# TREMO register map
File version: 1.6.2
CPU: CM4 r0p1, little endian, MPU, FPU, 3 interrupt priority bits
Registers are 32-bit, read-write, reset 0x0 unless marked. A register's access mark holds for its fields unless they carry their own. Offsets are from the block's base; [hi:lo] are bit positions; {n}, {i} and the like mark numbered series.

## SSP0
Base 0x40006000
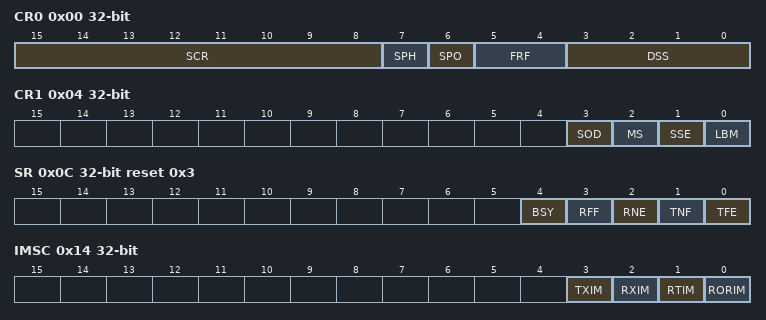
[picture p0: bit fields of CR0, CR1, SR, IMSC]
0x00 CR0 — control register 0
  [15:8] SCR — Serial clock rate
  [7] SPH — SSP phase setting
  [6] SPO — SSP polarity setting
  [5:4] FRF — SSP frame formats setting
  [3:0] DSS — Data width setting
0x04 CR1 — control register 1
  [3] SOD — SSP output disable in slave mode
  [2] MS — Master/slave mode selection
  [1] SSE — SSP enable
  [0] LBM — loopback mode
0x08 DR — data register
  [15:0] DATA
0x0C SR ro reset 0x3 — status register
  [4] BSY — SSP busy flag
  [3] RFF — RX FIFO full flag
  [2] RNE — RX FIFO not empty flag
  [1] TNF — TX FIFO not full flag
  [0] TFE — TX FIFO empty flag
0x10 CPSR — clock prescale register
  [7:0] CPSDVSR — Clock prescaler divider, must be an even number between 2~254
0x14 IMSC — interrupt mask set or clear register
  [3] TXIM — TX interrupt mask bit
  [2] RXIM — RX interrupt mask bit
  [1] RTIM — RX timeout interrupt mask bit
  [0] RORIM — RX overrun interrupt mask bit
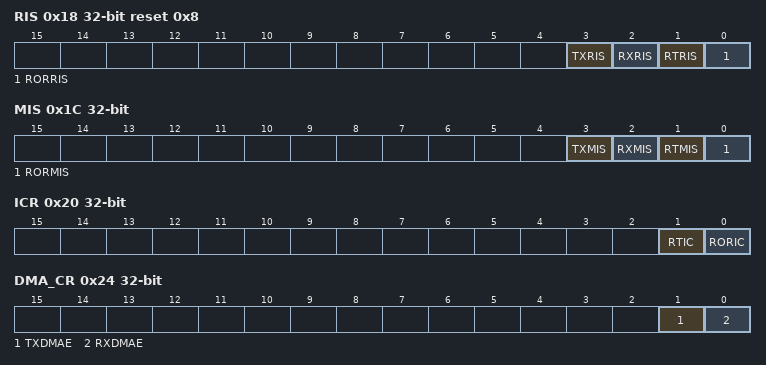
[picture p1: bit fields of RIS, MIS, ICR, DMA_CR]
0x18 RIS ro reset 0x8 — raw interrupt status register
  [3] TXRIS — TX raw interrupt status
  [2] RXRIS — RX raw interrupt status
  [1] RTRIS — RX timeout raw interrupt status
  [0] RORRIS — RX overrun raw interrupt status
0x1C MIS ro — masked interrupt status register
  [3] TXMIS — TX masked interrupt status
  [2] RXMIS — RX masked interrupt status
  [1] RTMIS — RX timeout masked interrupt status
  [0] RORMIS — RX overrun masked interrupt status
0x20 ICR wo — interrupt clear register
  [1] RTIC — RX timeout interrupt clear
  [0] RORIC — RX overrun interrupt clear
0x24 DMA_CR — DMA control register
  [1] TXDMAE — DMA TX enable
  [0] RXDMAE — DMA RX enable
{0xFE0+4i} PERIPH_ID{i} ro (i=0..3) — peripheral identification register {i}
{0xFF0+4i} PCELL_ID{i} ro (i=0..3) — prime cell identification register {i}

## SSP1
Base 0x40012000
Same registers: SSP2 0x40013000
Registers as SSP0; these are added or differ:
0x08 DR — data register
  [15:0] DATA — SSP TX/RX data

## LPUART — Low power UART
Base 0x40005000
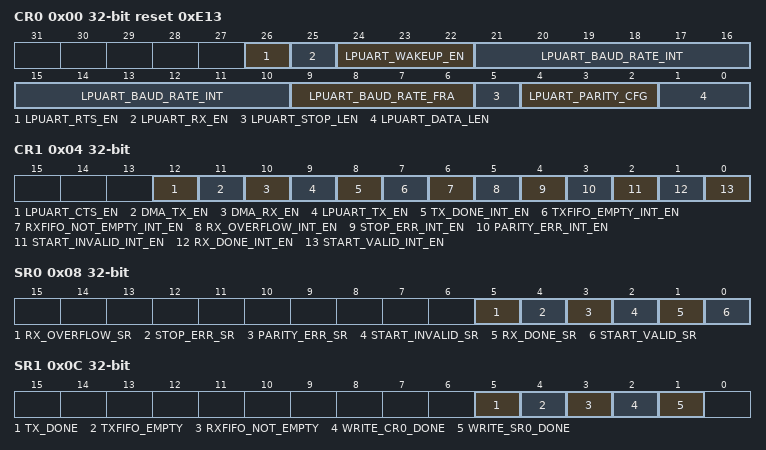
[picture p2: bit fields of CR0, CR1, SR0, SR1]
0x00 CR0 reset 0xE13 (reset mask 0x3FFFFFF) — control register 0
  [26] LPUART_RTS_EN — LPUART RTS flow control enable
  [25] LPUART_RX_EN — LPUART reception enable
  [24:22] LPUART_WAKEUP_EN — LPUART wakeup enable
  [21:10] LPUART_BAUD_RATE_INT — The integer part of the baud rate divisor
  [9:6] LPUART_BAUD_RATE_FRA — The fractional part of the baud rate divisor
  [5] LPUART_STOP_LEN — LPUART STOP bits configuration
  [4:2] LPUART_PARITY_CFG — LPUART parity bit configuration
  [1:0] LPUART_DATA_LEN — LPUART data length
0x04 CR1 — control register 1
  [12] LPUART_CTS_EN — LPUART CTS flow control enable
  [11] DMA_TX_EN — DMA transmission requests enable
  [10] DMA_RX_EN — DMA reception requests enable
  [9] LPUART_TX_EN — LPUART transmission enable
  [8] TX_DONE_INT_EN — TX_DONE interrupt enable
  [7] TXFIFO_EMPTY_INT_EN — TXFIFO_EMPTY interrupt enable
  [6] RXFIFO_NOT_EMPTY_INT_EN — RXFIFO_NOT_EMPTY interrupt enable
  [5] RX_OVERFLOW_INT_EN — RX_OVERFLOW interrupt enable
  [4] STOP_ERR_INT_EN — STOP_ERR interrupt enable
  [3] PARITY_ERR_INT_EN — PARITY_ERR interrupt enable
  [2] START_INVALID_INT_EN — START_INVALID interrupt enable
  [1] RX_DONE_INT_EN — RX_DONE interrupt enable
  [0] START_VALID_INT_EN — START_VALID interrupt enable
0x08 SR0 — status register 0
  [5] RX_OVERFLOW_SR — RX_OVERFLOW flag
  [4] STOP_ERR_SR — STOP_ERR flag
  [3] PARITY_ERR_SR — PARITY_ERR flag
  [2] START_INVALID_SR — START_INVALID flag
  [1] RX_DONE_SR — RX_DONE flag
  [0] START_VALID_SR — START_VALID flag
0x0C SR1 ro — status register 1
  [5] TX_DONE — TX_DONE flag
  [4] TXFIFO_EMPTY — TXFIFO_EMPTY flag
  [3] RXFIFO_NOT_EMPTY — RXFIFO_NOT_EMPTY flag
  [2] WRITE_CR0_DONE — The status of a write operation to the LPUART_CR0 register
  [1] WRITE_SR0_DONE — The status of a write operation to the LPUART_SR0 register
0x10 DATA
  [7:0] LPUART_DATA — LPUART TX/RX data
